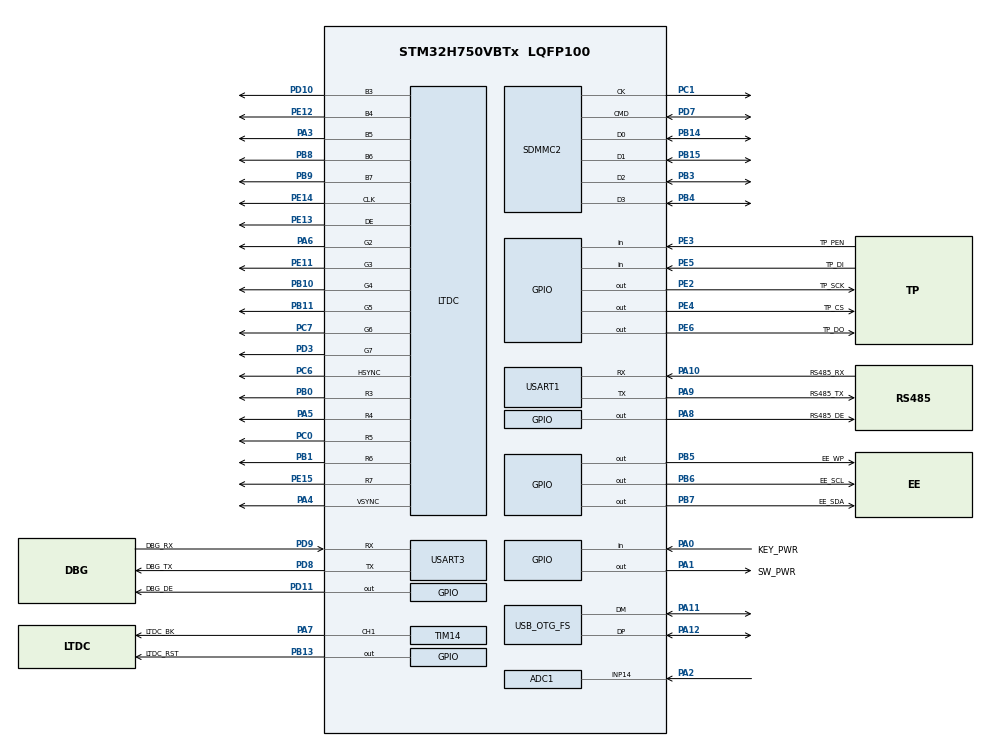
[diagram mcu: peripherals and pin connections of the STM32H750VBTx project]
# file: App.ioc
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ADC1.Channel-1\#ChannelRegularConversion=ADC_CHANNEL_14
ADC1.NbrOfConversionFlag=1
ADC1.OffsetNumber-1\#ChannelRegularConversion=ADC_OFFSET_NONE
ADC1.OffsetSignedSaturation-1\#ChannelRegularConversion=DISABLE
ADC1.Rank-1\#ChannelRegularConversion=1
ADC1.SamplingTime-1\#ChannelRegularConversion=ADC_SAMPLETIME_32CYCLES_5
ADC1.master=1
CORTEX_M7.AccessPermission-Cortex_Memory_Protection_Unit_Region0_Settings=MPU_REGION_FULL_ACCESS
CORTEX_M7.AccessPermission-Cortex_Memory_Protection_Unit_Region1_Settings=MPU_REGION_FULL_ACCESS
CORTEX_M7.AccessPermission-Cortex_Memory_Protection_Unit_Region2_Settings=MPU_REGION_FULL_ACCESS
CORTEX_M7.AccessPermission-Cortex_Memory_Protection_Unit_Region3_Settings=MPU_REGION_FULL_ACCESS
CORTEX_M7.AccessPermission-Cortex_Memory_Protection_Unit_Region4_Settings=MPU_REGION_FULL_ACCESS
CORTEX_M7.BaseAddress-Cortex_Memory_Protection_Unit_Region0_Settings=0x90000000
CORTEX_M7.BaseAddress-Cortex_Memory_Protection_Unit_Region1_Settings=0x20000000
CORTEX_M7.BaseAddress-Cortex_Memory_Protection_Unit_Region2_Settings=0x24000000
CORTEX_M7.BaseAddress-Cortex_Memory_Protection_Unit_Region3_Settings=0x30000000
CORTEX_M7.BaseAddress-Cortex_Memory_Protection_Unit_Region4_Settings=0x38000000
CORTEX_M7.CPU_DCache=Enabled
CORTEX_M7.CPU_ICache=Enabled
CORTEX_M7.Enable-Cortex_Memory_Protection_Unit_Region0_Settings=MPU_REGION_ENABLE
CORTEX_M7.Enable-Cortex_Memory_Protection_Unit_Region1_Settings=MPU_REGION_ENABLE
CORTEX_M7.Enable-Cortex_Memory_Protection_Unit_Region2_Settings=MPU_REGION_ENABLE
CORTEX_M7.Enable-Cortex_Memory_Protection_Unit_Region3_Settings=MPU_REGION_ENABLE
CORTEX_M7.Enable-Cortex_Memory_Protection_Unit_Region4_Settings=MPU_REGION_ENABLE
CORTEX_M7.IsBufferable-Cortex_Memory_Protection_Unit_Region0_Settings=MPU_ACCESS_BUFFERABLE
CORTEX_M7.IsBufferable-Cortex_Memory_Protection_Unit_Region1_Settings=MPU_ACCESS_BUFFERABLE
CORTEX_M7.IsBufferable-Cortex_Memory_Protection_Unit_Region2_Settings=MPU_ACCESS_BUFFERABLE
CORTEX_M7.IsBufferable-Cortex_Memory_Protection_Unit_Region3_Settings=MPU_ACCESS_BUFFERABLE
CORTEX_M7.IsBufferable-Cortex_Memory_Protection_Unit_Region4_Settings=MPU_ACCESS_BUFFERABLE
CORTEX_M7.IsCacheable-Cortex_Memory_Protection_Unit_Region0_Settings=MPU_ACCESS_CACHEABLE
CORTEX_M7.IsCacheable-Cortex_Memory_Protection_Unit_Region1_Settings=MPU_ACCESS_CACHEABLE
CORTEX_M7.IsCacheable-Cortex_Memory_Protection_Unit_Region2_Settings=MPU_ACCESS_CACHEABLE
CORTEX_M7.IsCacheable-Cortex_Memory_Protection_Unit_Region3_Settings=MPU_ACCESS_CACHEABLE
CORTEX_M7.IsCacheable-Cortex_Memory_Protection_Unit_Region4_Settings=MPU_ACCESS_CACHEABLE
CORTEX_M7.MPU_Control=MPU_PRIVILEGED_DEFAULT
CORTEX_M7.Size-Cortex_Memory_Protection_Unit_Region0_Settings=MPU_REGION_SIZE_32MB
CORTEX_M7.Size-Cortex_Memory_Protection_Unit_Region1_Settings=MPU_REGION_SIZE_128KB
CORTEX_M7.Size-Cortex_Memory_Protection_Unit_Region2_Settings=MPU_REGION_SIZE_512KB
CORTEX_M7.Size-Cortex_Memory_Protection_Unit_Region3_Settings=MPU_REGION_SIZE_512KB
CORTEX_M7.Size-Cortex_Memory_Protection_Unit_Region4_Settings=MPU_REGION_SIZE_64KB
LTDC.ActiveH=240
LTDC.ActiveW=320
LTDC.Alpha_L0=255
LTDC.BlendingFactor1_L0=LTDC_BLENDING_FACTOR1_PAxCA
LTDC.BlendingFactor2_L0=LTDC_BLENDING_FACTOR2_PAxCA
LTDC.FBStartAdress_L0=0x24000000
LTDC.HBP=43
LTDC.HFP=8
LTDC.HSync=4
LTDC.ImageHeight_L0=240
LTDC.ImageWidth_L0=320
LTDC.Layers=0
LTDC.PixelFormat_L0=LTDC_PIXEL_FORMAT_RGB565
LTDC.VBP=12
LTDC.VFP=8
LTDC.WindowX1_L0=320
LTDC.WindowY1_L0=240
Mcu.Family=STM32H7
Mcu.Name=STM32H750VBTx
Mcu.Package=LQFP100
NVIC.OTG_FS_IRQn=true\:0\:0\:false\:false\:true\:false\:true
NVIC.PriorityGroup=NVIC_PRIORITYGROUP_4
NVIC.SDMMC2_IRQn=true\:5\:0\:true\:false\:true\:true\:true
NVIC.TIM7_IRQn=true\:15\:0\:false\:false\:true\:false\:true
NVIC.TimeBase=TIM7_IRQn
NVIC.TimeBaseIP=TIM7
NVIC.USART1_IRQn=true\:0\:0\:false\:false\:false\:true\:false
NVIC.USART3_IRQn=true\:0\:0\:false\:false\:false\:true\:false
PA0.GPIO_Label=KEY_PWR
PA0.GPIO_PuPd=GPIO_PULLUP
PA0.Signal=GPIO_Input
PA1.GPIO_Label=SW_PWR
PA1.PinState=GPIO_PIN_SET
PA1.Signal=GPIO_Output
PA10.GPIO_Label=RS485_RX
PA10.GPIO_Speed=GPIO_SPEED_FREQ_HIGH
PA10.Mode=Asynchronous
PA10.Signal=USART1_RX
PA11.GPIO_Speed=GPIO_SPEED_FREQ_VERY_HIGH
PA11.Mode=Device_Only
PA11.Signal=USB_OTG_FS_DM
PA12.GPIO_Speed=GPIO_SPEED_FREQ_VERY_HIGH
PA12.Mode=Device_Only
PA12.Signal=USB_OTG_FS_DP
PA13\ (JTMS/SWDIO).Mode=Serial_Wire
PA13\ (JTMS/SWDIO).Signal=DEBUG_JTMS-SWDIO
PA14\ (JTCK/SWCLK).Mode=Serial_Wire
PA14\ (JTCK/SWCLK).Signal=DEBUG_JTCK-SWCLK
PA2.Signal=ADCx_INP14
PA3.GPIO_Speed=GPIO_SPEED_FREQ_VERY_HIGH
PA3.Mode=RGB565
PA3.Signal=LTDC_B5
PA4.GPIO_Speed=GPIO_SPEED_FREQ_VERY_HIGH
PA4.Mode=RGB565
PA4.Signal=LTDC_VSYNC
PA5.GPIO_Speed=GPIO_SPEED_FREQ_VERY_HIGH
PA5.Mode=RGB565
PA5.Signal=LTDC_R4
PA6.GPIO_Speed=GPIO_SPEED_FREQ_VERY_HIGH
PA6.Mode=RGB565
PA6.Signal=LTDC_G2
PA7.GPIO_Label=LTDC_BK
PA7.GPIO_Speed=GPIO_SPEED_FREQ_HIGH
PA7.Signal=S_TIM14_CH1
PA8.GPIO_Label=RS485_DE
PA8.PinState=GPIO_PIN_SET
PA8.Signal=GPIO_Output
PA9.GPIO_Label=RS485_TX
PA9.GPIO_Speed=GPIO_SPEED_FREQ_HIGH
PA9.Mode=Asynchronous
PA9.Signal=USART1_TX
PB0.GPIO_Speed=GPIO_SPEED_FREQ_VERY_HIGH
PB0.Mode=RGB565
PB0.Signal=LTDC_R3
PB1.GPIO_Speed=GPIO_SPEED_FREQ_VERY_HIGH
PB1.Mode=RGB565
PB1.Signal=LTDC_R6
PB10.GPIO_Speed=GPIO_SPEED_FREQ_VERY_HIGH
PB10.Mode=RGB565
PB10.Signal=LTDC_G4
PB11.GPIO_Speed=GPIO_SPEED_FREQ_VERY_HIGH
PB11.Mode=RGB565
PB11.Signal=LTDC_G5
PB13.GPIO_Label=LTDC_RST
PB13.GPIO_Speed=GPIO_SPEED_FREQ_LOW
PB13.PinState=GPIO_PIN_SET
PB13.Signal=GPIO_Output
PB14.Mode=SD_4_bits_Wide_bus
PB14.Signal=SDMMC2_D0
PB15.Mode=SD_4_bits_Wide_bus
PB15.Signal=SDMMC2_D1
PB3\ (JTDO/TRACESWO).Mode=SD_4_bits_Wide_bus
PB3\ (JTDO/TRACESWO).Signal=SDMMC2_D2
PB4\ (NJTRST).Mode=SD_4_bits_Wide_bus
PB4\ (NJTRST).Signal=SDMMC2_D3
PB5.GPIO_Label=EE_WP
PB5.GPIO_Speed=GPIO_SPEED_FREQ_HIGH
PB5.PinState=GPIO_PIN_RESET
PB5.Signal=GPIO_Output
PB6.GPIO_Label=EE_SCL
PB6.GPIO_Speed=GPIO_SPEED_FREQ_HIGH
PB6.PinState=GPIO_PIN_SET
PB6.Signal=GPIO_Output
PB7.GPIO_Label=EE_SDA
PB7.GPIO_Speed=GPIO_SPEED_FREQ_HIGH
PB7.PinState=GPIO_PIN_SET
PB7.Signal=GPIO_Output
PB8.GPIO_Speed=GPIO_SPEED_FREQ_VERY_HIGH
PB8.Mode=RGB565
PB8.Signal=LTDC_B6
PB9.GPIO_Speed=GPIO_SPEED_FREQ_VERY_HIGH
PB9.Mode=RGB565
PB9.Signal=LTDC_B7
PC0.GPIO_Speed=GPIO_SPEED_FREQ_VERY_HIGH
PC0.Mode=RGB565
PC0.Signal=LTDC_R5
PC1.Mode=SD_4_bits_Wide_bus
PC1.Signal=SDMMC2_CK
PC14-OSC32_IN\ (OSC32_IN).Mode=LSE-External-Oscillator
PC14-OSC32_IN\ (OSC32_IN).Signal=RCC_OSC32_IN
PC15-OSC32_OUT\ (OSC32_OUT).Mode=LSE-External-Oscillator
PC15-OSC32_OUT\ (OSC32_OUT).Signal=RCC_OSC32_OUT
PC6.GPIO_Speed=GPIO_SPEED_FREQ_VERY_HIGH
PC6.Mode=RGB565
PC6.Signal=LTDC_HSYNC
PC7.GPIO_Speed=GPIO_SPEED_FREQ_VERY_HIGH
PC7.Mode=RGB565
PC7.Signal=LTDC_G6
PD10.GPIO_Speed=GPIO_SPEED_FREQ_VERY_HIGH
PD10.Mode=RGB565
PD10.Signal=LTDC_B3
PD11.GPIO_Label=DBG_DE
PD11.PinState=GPIO_PIN_SET
PD11.Signal=GPIO_Output
PD3.GPIO_Speed=GPIO_SPEED_FREQ_VERY_HIGH
PD3.Mode=RGB565
PD3.Signal=LTDC_G7
PD7.Mode=SD_4_bits_Wide_bus
PD7.Signal=SDMMC2_CMD
PD8.GPIO_Label=DBG_TX
PD8.GPIO_Speed=GPIO_SPEED_FREQ_HIGH
PD8.Mode=Asynchronous
PD8.Signal=USART3_TX
PD9.GPIO_Label=DBG_RX
PD9.GPIO_Speed=GPIO_SPEED_FREQ_HIGH
PD9.Mode=Asynchronous
PD9.Signal=USART3_RX
PE11.GPIO_Speed=GPIO_SPEED_FREQ_VERY_HIGH
PE11.Mode=RGB565
PE11.Signal=LTDC_G3
PE12.GPIO_Speed=GPIO_SPEED_FREQ_VERY_HIGH
PE12.Mode=RGB565
PE12.Signal=LTDC_B4
PE13.GPIO_Speed=GPIO_SPEED_FREQ_VERY_HIGH
PE13.Mode=RGB565
PE13.Signal=LTDC_DE
PE14.GPIO_Speed=GPIO_SPEED_FREQ_VERY_HIGH
PE14.Mode=RGB565
PE14.Signal=LTDC_CLK
PE15.GPIO_Speed=GPIO_SPEED_FREQ_VERY_HIGH
PE15.Mode=RGB565
PE15.Signal=LTDC_R7
PE2.GPIO_Label=TP_SCK
PE2.GPIO_PuPd=GPIO_PULLUP
PE2.GPIO_Speed=GPIO_SPEED_FREQ_HIGH
PE2.PinState=GPIO_PIN_SET
PE2.Signal=GPIO_Output
PE3.GPIO_Label=TP_PEN
PE3.GPIO_PuPd=GPIO_PULLUP
PE3.Signal=GPIO_Input
PE4.GPIO_Label=TP_CS
PE4.GPIO_PuPd=GPIO_PULLUP
PE4.GPIO_Speed=GPIO_SPEED_FREQ_HIGH
PE4.PinState=GPIO_PIN_SET
PE4.Signal=GPIO_Output
PE5.GPIO_Label=TP_DI
PE5.Signal=GPIO_Input
PE6.GPIO_Label=TP_DO
PE6.GPIO_PuPd=GPIO_PULLUP
PE6.GPIO_Speed=GPIO_SPEED_FREQ_HIGH
PE6.PinState=GPIO_PIN_SET
PE6.Signal=GPIO_Output
PH0-OSC_IN\ (PH0).Mode=HSE-External-Oscillator
PH0-OSC_IN\ (PH0).Signal=RCC_OSC_IN
PH1-OSC_OUT\ (PH1).Mode=HSE-External-Oscillator
PH1-OSC_OUT\ (PH1).Signal=RCC_OSC_OUT
ProjectManager.HeapSize=0x4000
ProjectManager.StackSize=0x4000
ProjectManager.TargetToolchain=EWARM V8
RCC.ADCFreq_Value=72000000
RCC.APB1Freq_Value=120000000
RCC.APB2Freq_Value=120000000
RCC.APB3Freq_Value=120000000
RCC.APB4Freq_Value=120000000
RCC.CortexFreq_Value=480000000
RCC.D1PPRE=RCC_APB3_DIV2
RCC.D2PPRE1=RCC_APB1_DIV2
RCC.D2PPRE2=RCC_APB2_DIV2
RCC.D3PPRE=RCC_APB4_DIV2
RCC.DIVM1=5
RCC.DIVM2=5
RCC.DIVM3=5
RCC.DIVN1=192
RCC.DIVN2=72
RCC.DIVN3=30
RCC.DIVP2=5
RCC.DIVQ1=4
RCC.DIVR3=25
RCC.HCLKFreq_Value=240000000
RCC.HPRE=RCC_HCLK_DIV2
RCC.PLLSourceVirtual=RCC_PLLSOURCE_HSE
RCC.RTCClockSelection=RCC_RTCCLKSOURCE_LSE
RCC.SYSCLKFreq_VALUE=480000000
RCC.SYSCLKSource=RCC_SYSCLKSOURCE_PLLCLK
RCC.USBCLockSelection=RCC_USBCLKSOURCE_HSI48
RCC.USBFreq_Value=48000000
RTC.Format=RTC_FORMAT_BIN
RTC.WeekDay=RTC_WEEKDAY_FRIDAY
RTC.Year=21
SDMMC2.ClockDiv=2
SDMMC2.HardwareFlowControl=SDMMC_HARDWARE_FLOW_CONTROL_ENABLE
SH.ADCx_INP14.0=ADC1_INP14,IN14-Single-Ended
SH.S_TIM14_CH1.0=TIM14_CH1,PWM Generation1 CH1
TIM14.Channel=TIM_CHANNEL_1
TIM14.Period=100-1
TIM14.Prescaler=240-1
USART1.VirtualMode-Asynchronous=VM_ASYNC
USART3.VirtualMode-Asynchronous=VM_ASYNC
USB_DEVICE.CLASS_NAME_FS=CDC
USB_DEVICE.VirtualMode-CDC_FS=Cdc
USB_DEVICE.VirtualModeFS=Cdc_FS
USB_OTG_FS.VirtualMode=Device_Only
VP_RTC_VS_RTC_Activate.Mode=RTC_Enabled
VP_RTC_VS_RTC_Calendar.Mode=RTC_Calendar
VP_SYS_VS_tim7.Mode=TIM7
VP_TIM14_VS_ClockSourceINT.Mode=Enable_Timer
VP_USB_DEVICE_VS_USB_DEVICE_CDC_FS.Mode=CDC_FS
board=custom

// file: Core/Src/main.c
/* USER CODE BEGIN Header */
/**
  ******************************************************************************
  * @file           : main.c
  * @brief          : Main program body
  ******************************************************************************
  * @attention
  *
  * <h2><center>&copy; Copyright (c) 2021 STMicroelectronics.
  * All rights reserved.</center></h2>
  *
  * This software component is licensed by ST under BSD 3-Clause license,
  * the "License"; You may not use this file except in compliance with the
  * License. You may obtain a copy of the License at:
  *                        opensource.org/licenses/BSD-3-Clause
  *
  ******************************************************************************
  */
/* USER CODE END Header */
#include "main.h"
#include "adc.h"
#include "ltdc.h"
#include "rtc.h"
#include "sdmmc.h"
#include "tim.h"
#include "usart.h"
#include "usb_device.h"
#include "gpio.h"

/* USER CODE BEGIN Includes */
#include "includes.h"
/* USER CODE END Includes */

void SystemClock_Config(void);
static void MPU_Config(void);

int main(void)
{

  /* MPU Configuration--------------------------------------------------------*/
  MPU_Config();

  /* Enable I-Cache---------------------------------------------------------*/
  SCB_EnableICache();

  /* Enable D-Cache---------------------------------------------------------*/
  SCB_EnableDCache();

  /* MCU Configuration--------------------------------------------------------*/

  /* Reset of all peripherals, Initializes the Flash interface and the Systick. */
  HAL_Init();

  /* Configure the system clock */
  SystemClock_Config();

  /* Initialize all configured peripherals */
  MX_GPIO_Init();
  MX_RTC_Init();
  MX_USART3_UART_Init();
  MX_LTDC_Init();
  MX_TIM14_Init();
  MX_ADC1_Init();
  MX_USB_DEVICE_Init();
  MX_SDMMC2_SD_Init();
  MX_USART1_UART_Init();
  /* USER CODE BEGIN 2 */
  HAL_SuspendTick();
  tx_kernel_enter();
  /* USER CODE END 2 */

  /* Infinite loop */
  while (1)
  {

  }
}

void SystemClock_Config(void)
{
  RCC_OscInitTypeDef RCC_OscInitStruct = {0};
  RCC_ClkInitTypeDef RCC_ClkInitStruct = {0};

  /** Supply configuration update enable
  */
  HAL_PWREx_ConfigSupply(PWR_LDO_SUPPLY);
  /** Configure the main internal regulator output voltage
  */
  __HAL_PWR_VOLTAGESCALING_CONFIG(PWR_REGULATOR_VOLTAGE_SCALE0);

  while(!__HAL_PWR_GET_FLAG(PWR_FLAG_VOSRDY)) {}
  /** Configure LSE Drive Capability
  */
  HAL_PWR_EnableBkUpAccess();
  __HAL_RCC_LSEDRIVE_CONFIG(RCC_LSEDRIVE_LOW);
  /** Macro to configure the PLL clock source
  */
  __HAL_RCC_PLL_PLLSOURCE_CONFIG(RCC_PLLSOURCE_HSE);
  /** Initializes the RCC Oscillators according to the specified parameters
  * in the RCC_OscInitTypeDef structure.
  */
  RCC_OscInitStruct.OscillatorType = RCC_OSCILLATORTYPE_HSI48|RCC_OSCILLATORTYPE_HSE
                              |RCC_OSCILLATORTYPE_LSE;
  RCC_OscInitStruct.HSEState = RCC_HSE_ON;
  RCC_OscInitStruct.LSEState = RCC_LSE_ON;
  RCC_OscInitStruct.HSI48State = RCC_HSI48_ON;
  RCC_OscInitStruct.PLL.PLLState = RCC_PLL_ON;
  RCC_OscInitStruct.PLL.PLLSource = RCC_PLLSOURCE_HSE;
  RCC_OscInitStruct.PLL.PLLM = 5;
  RCC_OscInitStruct.PLL.PLLN = 192;
  RCC_OscInitStruct.PLL.PLLP = 2;
  RCC_OscInitStruct.PLL.PLLQ = 4;
  RCC_OscInitStruct.PLL.PLLR = 2;
  RCC_OscInitStruct.PLL.PLLRGE = RCC_PLL1VCIRANGE_2;
  RCC_OscInitStruct.PLL.PLLVCOSEL = RCC_PLL1VCOWIDE;
  RCC_OscInitStruct.PLL.PLLFRACN = 0;
  if (HAL_RCC_OscConfig(&RCC_OscInitStruct) != HAL_OK)
  {
    Error_Handler();
  }
  /** Initializes the CPU, AHB and APB buses clocks
  */
  RCC_ClkInitStruct.ClockType = RCC_CLOCKTYPE_HCLK|RCC_CLOCKTYPE_SYSCLK
                              |RCC_CLOCKTYPE_PCLK1|RCC_CLOCKTYPE_PCLK2
                              |RCC_CLOCKTYPE_D3PCLK1|RCC_CLOCKTYPE_D1PCLK1;
  RCC_ClkInitStruct.SYSCLKSource = RCC_SYSCLKSOURCE_PLLCLK;
  RCC_ClkInitStruct.SYSCLKDivider = RCC_SYSCLK_DIV1;
  RCC_ClkInitStruct.AHBCLKDivider = RCC_HCLK_DIV2;
  RCC_ClkInitStruct.APB3CLKDivider = RCC_APB3_DIV2;
  RCC_ClkInitStruct.APB1CLKDivider = RCC_APB1_DIV2;
  RCC_ClkInitStruct.APB2CLKDivider = RCC_APB2_DIV2;
  RCC_ClkInitStruct.APB4CLKDivider = RCC_APB4_DIV2;

  if (HAL_RCC_ClockConfig(&RCC_ClkInitStruct, FLASH_LATENCY_4) != HAL_OK)
  {
    Error_Handler();
  }
}

/* MPU Configuration */

void MPU_Config(void)
{
  MPU_Region_InitTypeDef MPU_InitStruct = {0};

  /* Disables the MPU */
  HAL_MPU_Disable();
  /** Initializes and configures the Region and the memory to be protected
  */
  MPU_InitStruct.Enable = MPU_REGION_ENABLE;
  MPU_InitStruct.Number = MPU_REGION_NUMBER0;
  MPU_InitStruct.BaseAddress = 0x90000000;
  MPU_InitStruct.Size = MPU_REGION_SIZE_32MB;
  MPU_InitStruct.SubRegionDisable = 0x0;
  MPU_InitStruct.TypeExtField = MPU_TEX_LEVEL0;
  MPU_InitStruct.AccessPermission = MPU_REGION_FULL_ACCESS;
  MPU_InitStruct.DisableExec = MPU_INSTRUCTION_ACCESS_ENABLE;
  MPU_InitStruct.IsShareable = MPU_ACCESS_NOT_SHAREABLE;
  MPU_InitStruct.IsCacheable = MPU_ACCESS_CACHEABLE;
  MPU_InitStruct.IsBufferable = MPU_ACCESS_BUFFERABLE;

  HAL_MPU_ConfigRegion(&MPU_InitStruct);
  /** Initializes and configures the Region and the memory to be protected
  */
  MPU_InitStruct.Number = MPU_REGION_NUMBER1;
  MPU_InitStruct.BaseAddress = 0x20000000;
  MPU_InitStruct.Size = MPU_REGION_SIZE_128KB;

  HAL_MPU_ConfigRegion(&MPU_InitStruct);
  /** Initializes and configures the Region and the memory to be protected
  */
  MPU_InitStruct.Number = MPU_REGION_NUMBER2;
  MPU_InitStruct.BaseAddress = 0x24000000;
  MPU_InitStruct.Size = MPU_REGION_SIZE_512KB;

  HAL_MPU_ConfigRegion(&MPU_InitStruct);
  /** Initializes and configures the Region and the memory to be protected
  */
  MPU_InitStruct.Number = MPU_REGION_NUMBER3;
  MPU_InitStruct.BaseAddress = 0x30000000;

  HAL_MPU_ConfigRegion(&MPU_InitStruct);
  /** Initializes and configures the Region and the memory to be protected
  */
  MPU_InitStruct.Number = MPU_REGION_NUMBER4;
  MPU_InitStruct.BaseAddress = 0x38000000;
  MPU_InitStruct.Size = MPU_REGION_SIZE_64KB;

  HAL_MPU_ConfigRegion(&MPU_InitStruct);
  /* Enables the MPU */
  HAL_MPU_Enable(MPU_PRIVILEGED_DEFAULT);

}

void HAL_TIM_PeriodElapsedCallback(TIM_HandleTypeDef *htim)
{
  if (htim->Instance == TIM7) {
    HAL_IncTick();
  }
}

void Error_Handler(void)
{
  __disable_irq();
  while (1)
  {
  }
}

/************************ (C) COPYRIGHT STMicroelectronics *****END OF FILE****/
